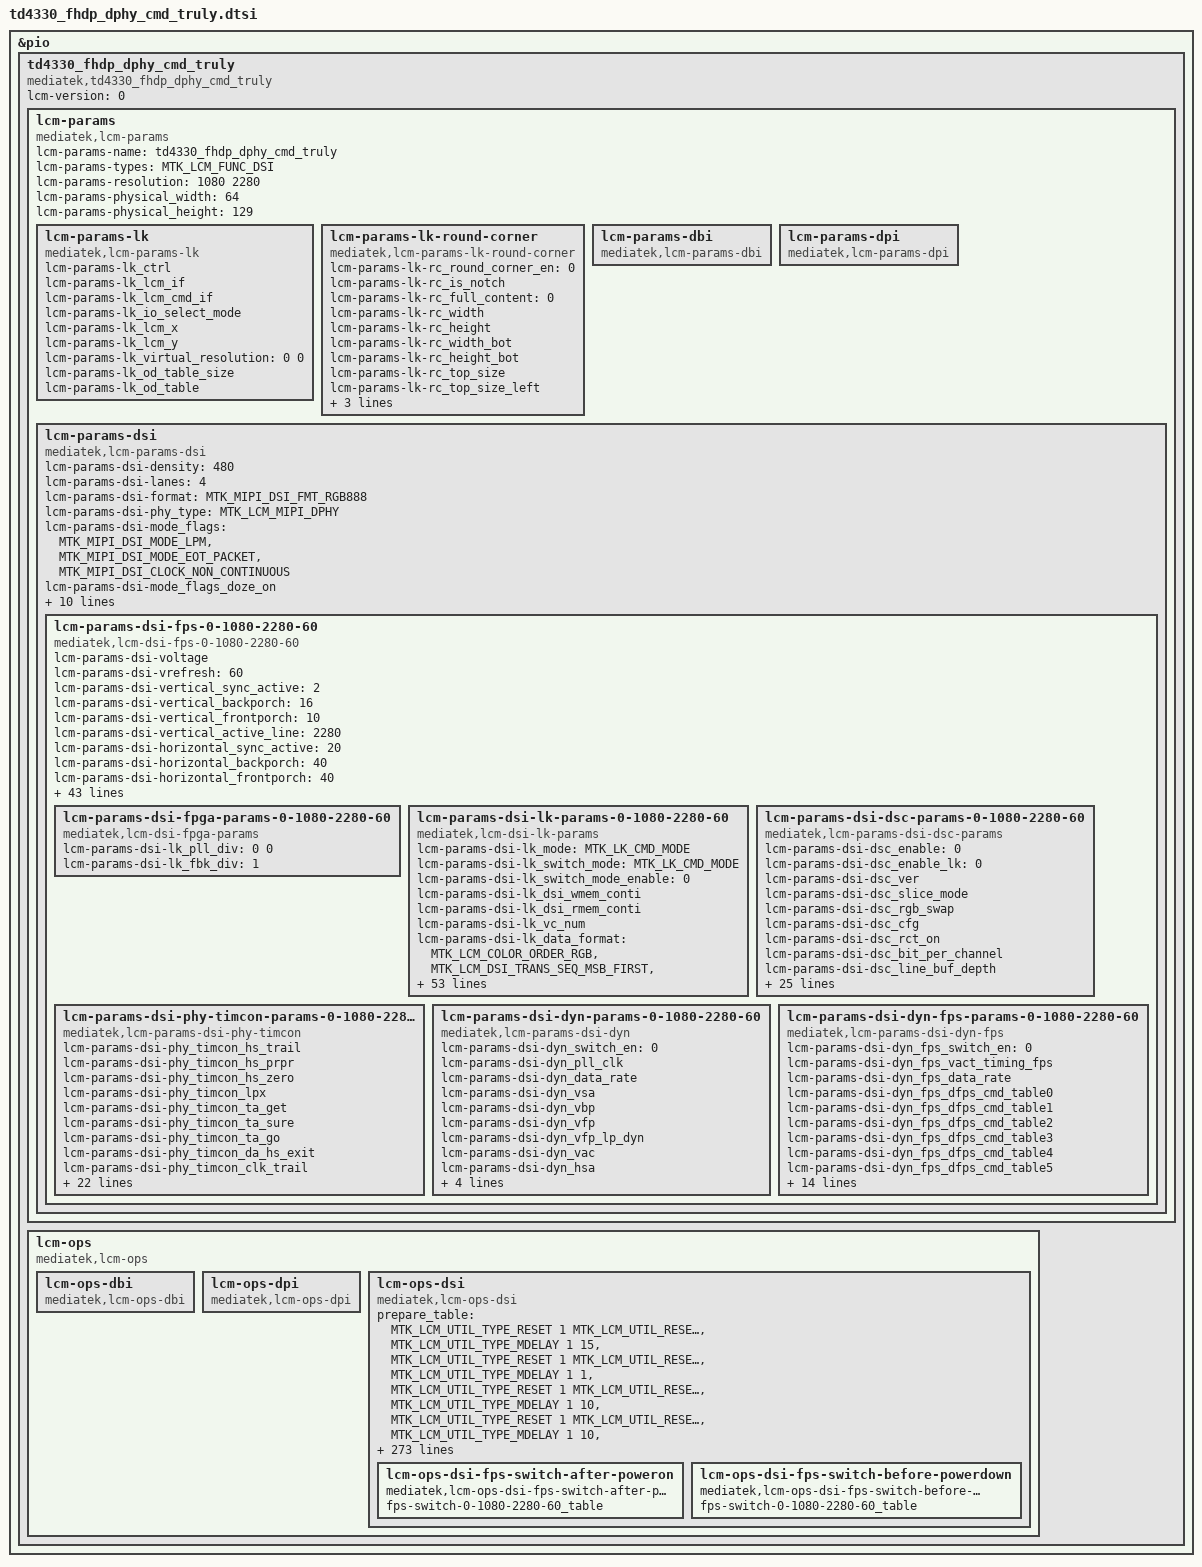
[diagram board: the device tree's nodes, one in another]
// SPDX-License-Identifier: GPL-2.0
/*
 * Device Tree defines for LCM settings
 * Copyright (c) 2021 MediaTek Inc.
 */

#include "mtk_lcm_settings.h"

&pio {
	td4330_fhdp_dphy_cmd_truly: td4330_fhdp_dphy_cmd_truly {
		compatible = "mediatek,td4330_fhdp_dphy_cmd_truly";
		lcm-version = <0>;

		lcm-params{
			compatible = "mediatek,lcm-params";
			lcm-params-name = "td4330_fhdp_dphy_cmd_truly";
			lcm-params-types = <MTK_LCM_FUNC_DSI>;
			lcm-params-resolution = <1080 2280>;
			lcm-params-physical_width = <64>;
			lcm-params-physical_height = <129>;

			/* lk support */
			lcm-params-lk {
				compatible = "mediatek,lcm-params-lk";
				lcm-params-lk_ctrl;
				lcm-params-lk_lcm_if;
				lcm-params-lk_lcm_cmd_if;
				lcm-params-lk_io_select_mode;
				lcm-params-lk_lcm_x;
				lcm-params-lk_lcm_y;
				lcm-params-lk_virtual_resolution = <0 0>;
				lcm-params-lk_od_table_size;
				lcm-params-lk_od_table;
			};

			lcm-params-lk-round-corner {
				compatible = "mediatek,lcm-params-lk-round-corner";
				lcm-params-lk-rc_round_corner_en = <0>;
				lcm-params-lk-rc_is_notch;
				lcm-params-lk-rc_full_content = <0>;
				lcm-params-lk-rc_width;
				lcm-params-lk-rc_height;
				lcm-params-lk-rc_width_bot;
				lcm-params-lk-rc_height_bot;
				lcm-params-lk-rc_top_size;
				lcm-params-lk-rc_top_size_left;
				lcm-params-lk-rc_top_size_right;
				lcm-params-lk-rc_bottom_size;
				lcm-params-lk-rc_pattern_name;
			};

			lcm-params-dbi {
				compatible = "mediatek,lcm-params-dbi";
				/* future reserved for dbi interfaces */
			};

			lcm-params-dpi {
				compatible = "mediatek,lcm-params-dpi";
				/* future reserved for dpi interfaces */
			};

			lcm-params-dsi {
				compatible = "mediatek,lcm-params-dsi";
				lcm-params-dsi-density = <480>;
				lcm-params-dsi-lanes = <4>;
				lcm-params-dsi-format = <MTK_MIPI_DSI_FMT_RGB888>;
				lcm-params-dsi-phy_type = <MTK_LCM_MIPI_DPHY>;
				lcm-params-dsi-mode_flags = <MTK_MIPI_DSI_MODE_LPM>,
						<MTK_MIPI_DSI_MODE_EOT_PACKET>,
						<MTK_MIPI_DSI_CLOCK_NON_CONTINUOUS>;
				lcm-params-dsi-mode_flags_doze_on;
				lcm-params-dsi-mode_flags_doze_off;

				lcm-params-dsi-need_fake_resolution;
				lcm-params-dsi-fake_resolution = <1080 2280>;

				lcm_gpio_list = <&pio 42 0>, /* gpio list*/
					<&pio 28 0>,
					<&pio 29 0>;
				pinctrl-names = "gpio1", "gpio2", "gpio3";
				pinctrl-0;
				pinctrl-1;
				pinctrl-2;
				status = "okay";

				lcm-params-dsi-default_mode = <0>;
				lcm-params-dsi-mode_count = <1>;
				lcm-params-dsi-mode_list =
					<0 1080 2280 60>;

				lcm-params-dsi-fps-0-1080-2280-60 {
					compatible = "mediatek,lcm-dsi-fps-0-1080-2280-60";
					lcm-params-dsi-voltage;

					/* drm_display_mode */
					lcm-params-dsi-vrefresh = <60>;
					lcm-params-dsi-vertical_sync_active = <2>;
					lcm-params-dsi-vertical_backporch = <16>;
					lcm-params-dsi-vertical_frontporch = <10>;
					lcm-params-dsi-vertical_active_line = <2280>;
					lcm-params-dsi-horizontal_sync_active = <20>;
					lcm-params-dsi-horizontal_backporch = <40>;
					lcm-params-dsi-horizontal_frontporch = <40>;
					lcm-params-dsi-horizontal_active_pixel = <1080>;
					lcm-params-dsi-pixel_clock = <163406>;
					lcm-params-dsi-hskew;
					lcm-params-dsi-vscan;

					/* mtk_panel_params */
					lcm-params-dsi-pll_clock = <525>;
					lcm-params-dsi-data_rate;
					lcm-params-dsi-vfp_for_low_power = <750>;
					lcm-params-dsi-ssc_disable;
					lcm-params-dsi-ssc_range;
					lcm-params-dsi-lcm_color_mode;
					lcm-params-dsi-min_luminance;
					lcm-params-dsi-average_luminance;
					lcm-params-dsi-max_luminance;
					lcm-params-dsi-round_corner_en = <0>;
					lcm-params-dsi-corner_pattern_height;
					lcm-params-dsi-corner_pattern_height_bot;
					lcm-params-dsi-corner_pattern_tp_size;
					lcm-params-dsi-corner_pattern_tp_size_left;
					lcm-params-dsi-corner_pattern_tp_size_right;
					lcm-params-dsi-corner_pattern_name;
					lcm-params-dsi-physical_width_um;
					lcm-params-dsi-physical_height_um;
					lcm-params-dsi-output_mode = <MTK_LCM_PANEL_SINGLE_PORT>;
					lcm-params-dsi-lcm_cmd_if;
					lcm-params-dsi-hbm_en_time;
					lcm-params-dsi-hbm_dis_time;
					lcm-params-dsi-lcm_index;
					lcm-params-dsi-wait_sof_before_dec_vfp;
					lcm-params-dsi-doze_delay;
					lcm-params-dsi-lfr_enable;
					lcm-params-dsi-lfr_minimum_fps;
					lcm-params-dsi-msync2_enable;
					lcm-params-dsi-max_vfp_for_msync;

					/* lane swap */
					lcm-params-dsi-lane_swap_en;
					lcm-params-dsi-lane_swap0;
					lcm-params-dsi-lane_swap1;

					/* esd check table */
					lcm-params-dsi-cust_esd_check = <0>;
					lcm-params-dsi-esd_check_enable = <1>;
					lcm-params-dsi-lcm_esd_check_table0 = <0x0A 0x01 0x1C 0x0>;
					lcm-params-dsi-lcm_esd_check_table1;
					lcm-params-dsi-lcm_esd_check_table2;

					/* fpga support */
					lcm-params-dsi-fpga-params-0-1080-2280-60 {
						compatible = "mediatek,lcm-dsi-fpga-params";

						lcm-params-dsi-lk_pll_div = <0 0>;
						lcm-params-dsi-lk_fbk_div = <1>;
					};

					/* lk support */
					lcm-params-dsi-lk-params-0-1080-2280-60 {
						compatible = "mediatek,lcm-dsi-lk-params";
						lcm-params-dsi-lk_mode = <MTK_LK_CMD_MODE>;
						lcm-params-dsi-lk_switch_mode = <MTK_LK_CMD_MODE>;
						lcm-params-dsi-lk_switch_mode_enable = <0>;
						lcm-params-dsi-lk_dsi_wmem_conti;
						lcm-params-dsi-lk_dsi_rmem_conti;
						lcm-params-dsi-lk_vc_num;
						lcm-params-dsi-lk_data_format =
							<MTK_LCM_COLOR_ORDER_RGB>,
							<MTK_LCM_DSI_TRANS_SEQ_MSB_FIRST>,
							<MTK_LCM_DSI_PADDING_ON_LSB>,
							<MTK_LCM_DSI_FORMAT_RGB888>;
						lcm-params-dsi-lk_intermediat_buffer_num;
						lcm-params-dsi-lk_ps =
							<MTK_LCM_PACKED_PS_24BIT_RGB888>;
						lcm-params-dsi-lk_word_count;
						lcm-params-dsi-lk_packet_size = <256>;

						lcm-params-dsi-lk_horizontal_blanking_pixel;
						lcm-params-dsi-lk_bllp;
						lcm-params-dsi-lk_line_byte;
						lcm-params-dsi-lk_horizontal_sync_active_byte;
						lcm-params-dsi-lk_horizontal_backporch_byte;
						lcm-params-dsi-lk_horizontal_frontporch_byte;
						lcm-params-dsi-lk_rgb_byte;
						lcm-params-dsi-lk_horizontal_sync_active_word_count;
						lcm-params-dsi-lk_horizontal_backporch_word_count;
						lcm-params-dsi-lk_horizontal_frontporch_word_count;
						lcm-params-dsi-lk_pll_select;
						lcm-params-dsi-lk_pll_div;
						lcm-params-dsi-lk_fbk_div;
						lcm-params-dsi-lk_fbk_sel;
						lcm-params-dsi-lk_rg = <0 0 0>;
						lcm-params-dsi-lk_dsi_clock;
						lcm-params-dsi-lk_ssc_disable = <1>;
						lcm-params-dsi-lk_ssc_range;
						lcm-params-dsi-lk_compatibility_for_nvk;
						lcm-params-dsi-lk_cont_clock;
						lcm-params-dsi-lk_ufoe_enable;
						lcm-params-dsi-lk_ufoe_params = <0 0 0 0>;
						lcm-params-dsi-lk_edp_panel;
						lcm-params-dsi-lk_lcm_int_te_monitor;
						lcm-params-dsi-lk_lcm_int_te_period;
						lcm-params-dsi-lk_lcm_ext_te_monitor;
						lcm-params-dsi-lk_lcm_ext_te_period;
						lcm-params-dsi-lk_noncont_clock;
						lcm-params-dsi-lk_noncont_clock_period;
						lcm-params-dsi-lk_clk_lp_per_line_enable;
						lcm-params-dsi-lk_dual_dsi_type;
						lcm-params-dsi-lk_mixmode_enable;
						lcm-params-dsi-lk_mixmode_mipi_clock;
						lcm-params-dsi-lk_pwm_fps;
						lcm-params-dsi-lk_pll_clock_lp;
						lcm-params-dsi-lk_ulps_sw_enable;
						lcm-params-dsi-lk_null_packet_en;
						lcm-params-dsi-lk_vact_fps;
						lcm-params-dsi-lk_send_frame_enable;
						lcm-params-dsi-lk_lfr_enable;
						lcm-params-dsi-lk_lfr_mode;
						lcm-params-dsi-lk_lfr_type;
						lcm-params-dsi-lk_lfr_skip_num;
						lcm-params-dsi-lk_ext_te_edge;
						lcm-params-dsi-lk_eint_disable;
						lcm-params-dsi-lk_phy_sel = <0 0 0 0>;
					};

					lcm-params-dsi-dsc-params-0-1080-2280-60 {
						compatible =
							"mediatek,lcm-params-dsi-dsc-params";
						lcm-params-dsi-dsc_enable = <0>;
						lcm-params-dsi-dsc_enable_lk = <0>;
						lcm-params-dsi-dsc_ver;
						lcm-params-dsi-dsc_slice_mode;
						lcm-params-dsi-dsc_rgb_swap;
						lcm-params-dsi-dsc_cfg;
						lcm-params-dsi-dsc_rct_on;
						lcm-params-dsi-dsc_bit_per_channel;
						lcm-params-dsi-dsc_line_buf_depth;
						lcm-params-dsi-dsc_bp_enable;
						lcm-params-dsi-dsc_bit_per_pixel;
						lcm-params-dsi-dsc_pic_height;
						lcm-params-dsi-dsc_pic_width;
						lcm-params-dsi-dsc_slice_height;
						lcm-params-dsi-dsc_slice_width;
						lcm-params-dsi-dsc_chunk_size;
						lcm-params-dsi-dsc_xmit_delay;
						lcm-params-dsi-dsc_dec_delay;
						lcm-params-dsi-dsc_scale_value;
						lcm-params-dsi-dsc_increment_interval;
						lcm-params-dsi-dsc_decrement_interval;
						lcm-params-dsi-dsc_line_bpg_offset;
						lcm-params-dsi-dsc_nfl_bpg_offset;
						lcm-params-dsi-dsc_slice_bpg_offset;
						lcm-params-dsi-dsc_initial_offset;
						lcm-params-dsi-dsc_final_offset;
						lcm-params-dsi-dsc_flatness_minqp;
						lcm-params-dsi-dsc_flatness_maxqp;
						lcm-params-dsi-dsc_rc_model_size;
						lcm-params-dsi-dsc_rc_edge_factor;
						lcm-params-dsi-dsc_rc_quant_incr_limit0;
						lcm-params-dsi-dsc_rc_quant_incr_limit1;
						lcm-params-dsi-dsc_rc_tgt_offset_hi;
						lcm-params-dsi-dsc_rc_tgt_offset_lo;
					};

					lcm-params-dsi-phy-timcon-params-0-1080-2280-60 {
						compatible =
							"mediatek,lcm-params-dsi-phy-timcon";
						lcm-params-dsi-phy_timcon_hs_trail;
						lcm-params-dsi-phy_timcon_hs_prpr;
						lcm-params-dsi-phy_timcon_hs_zero;
						lcm-params-dsi-phy_timcon_lpx;
						lcm-params-dsi-phy_timcon_ta_get;
						lcm-params-dsi-phy_timcon_ta_sure;
						lcm-params-dsi-phy_timcon_ta_go;
						lcm-params-dsi-phy_timcon_da_hs_exit;
						lcm-params-dsi-phy_timcon_clk_trail;
						lcm-params-dsi-phy_timcon_cont_det;
						lcm-params-dsi-phy_timcon_da_hs_sync;
						lcm-params-dsi-phy_timcon_clk_zero;
						lcm-params-dsi-phy_timcon_clk_prpr;
						lcm-params-dsi-phy_timcon_clk_exit;
						lcm-params-dsi-phy_timcon_clk_post;

						/* lk support */
						lcm-params-dsi-phy_timcon_lk_hs_trail;
						lcm-params-dsi-phy_timcon_lk_hs_zero;
						lcm-params-dsi-phy_timcon_lk_hs_prpr;
						lcm-params-dsi-phy_timcon_lk_lpx;
						lcm-params-dsi-phy_timcon_lk_ta_sack;
						lcm-params-dsi-phy_timcon_lk_ta_get;
						lcm-params-dsi-phy_timcon_lk_ta_sure;
						lcm-params-dsi-phy_timcon_lk_ta_go;
						lcm-params-dsi-phy_timcon_lk_clk_trail;
						lcm-params-dsi-phy_timcon_lk_clk_zero;
						lcm-params-dsi-phy_timcon_lk_lpx_wait;
						lcm-params-dsi-phy_timcon_lk_cont_det;
						lcm-params-dsi-phy_timcon_lk_clk_hs_prpr;
						lcm-params-dsi-phy_timcon_lk_clk_hs_post;
						lcm-params-dsi-phy_timcon_lk_da_hs_exit;
						lcm-params-dsi-phy_timcon_lk_clk_hs_exit;
					};

					lcm-params-dsi-dyn-params-0-1080-2280-60 {
						compatible =
							"mediatek,lcm-params-dsi-dyn";
						lcm-params-dsi-dyn_switch_en = <0>;
						lcm-params-dsi-dyn_pll_clk;
						lcm-params-dsi-dyn_data_rate;
						lcm-params-dsi-dyn_vsa;
						lcm-params-dsi-dyn_vbp;
						lcm-params-dsi-dyn_vfp;
						lcm-params-dsi-dyn_vfp_lp_dyn;
						lcm-params-dsi-dyn_vac;
						lcm-params-dsi-dyn_hsa;
						lcm-params-dsi-dyn_hbp;
						lcm-params-dsi-dyn_hfp;
						lcm-params-dsi-dyn_hac;
						lcm-params-dsi-dyn_max_vfp_for_msync_dyn;
					};

					lcm-params-dsi-dyn-fps-params-0-1080-2280-60 {
						compatible =
							"mediatek,lcm-params-dsi-dyn-fps";
						lcm-params-dsi-dyn_fps_switch_en = <0>;
						lcm-params-dsi-dyn_fps_vact_timing_fps;
						lcm-params-dsi-dyn_fps_data_rate;
						lcm-params-dsi-dyn_fps_dfps_cmd_table0;
						lcm-params-dsi-dyn_fps_dfps_cmd_table1;
						lcm-params-dsi-dyn_fps_dfps_cmd_table2;
						lcm-params-dsi-dyn_fps_dfps_cmd_table3;
						lcm-params-dsi-dyn_fps_dfps_cmd_table4;
						lcm-params-dsi-dyn_fps_dfps_cmd_table5;
						lcm-params-dsi-dyn_fps_dfps_cmd_table6;
						lcm-params-dsi-dyn_fps_dfps_cmd_table7;
						lcm-params-dsi-dyn_fps_dfps_cmd_table8;
						lcm-params-dsi-dyn_fps_dfps_cmd_table9;
						lcm-params-dsi-dyn_fps_dfps_cmd_table10;
						lcm-params-dsi-dyn_fps_dfps_cmd_table11;
						lcm-params-dsi-dyn_fps_dfps_cmd_table12;
						lcm-params-dsi-dyn_fps_dfps_cmd_table13;
						lcm-params-dsi-dyn_fps_dfps_cmd_table14;
						lcm-params-dsi-dyn_fps_dfps_cmd_table15;
						lcm-params-dsi-dyn_fps_dfps_cmd_table16;
						lcm-params-dsi-dyn_fps_dfps_cmd_table17;
						lcm-params-dsi-dyn_fps_dfps_cmd_table18;
						lcm-params-dsi-dyn_fps_dfps_cmd_table19;
					};
				};
			};
		};

		lcm-ops {
			compatible = "mediatek,lcm-ops";
			lcm-ops-dbi {
				compatible = "mediatek,lcm-ops-dbi";
				/* future reserved for dbi interfaces*/
			};

			lcm-ops-dpi {
				compatible = "mediatek,lcm-ops-dpi";
				/* future reserved for dpi interfaces*/
			};

			lcm-ops-dsi {
				compatible = "mediatek,lcm-ops-dsi";
				prepare_table = <MTK_LCM_UTIL_TYPE_RESET 1 MTK_LCM_UTIL_RESET_LOW>,
					<MTK_LCM_UTIL_TYPE_MDELAY 1 15>,
					<MTK_LCM_UTIL_TYPE_RESET 1 MTK_LCM_UTIL_RESET_HIGH>,
					<MTK_LCM_UTIL_TYPE_MDELAY 1 1>,
					<MTK_LCM_UTIL_TYPE_RESET 1 MTK_LCM_UTIL_RESET_LOW>,
					<MTK_LCM_UTIL_TYPE_MDELAY 1 10>,
					<MTK_LCM_UTIL_TYPE_RESET 1 MTK_LCM_UTIL_RESET_HIGH>,
					<MTK_LCM_UTIL_TYPE_MDELAY 1 10>,
					<MTK_LCM_CMD_TYPE_WRITE_BUFFER 2 0xB0 0x00>,
					<MTK_LCM_CMD_TYPE_WRITE_BUFFER 13>,
						<0xB6 0x30 0x6B 0x00 0x06 0x03 0x0A 0x13 0x1A 0x6C>,
						<0x18 0x19 0x02>,
					<MTK_LCM_CMD_TYPE_WRITE_BUFFER 5>,
						<0xB7 0x40 0x00 0x00 0x00>,
					<MTK_LCM_CMD_TYPE_WRITE_BUFFER 8>,
						<0xB8 0x57 0x3d 0x19 0xbe 0x1e 0x0a 0x0a>,
					<MTK_LCM_CMD_TYPE_WRITE_BUFFER 8>,
						<0xB9 0x6f 0x3d 0x28 0xbe 0x3c 0x14 0x0a>,
					<MTK_LCM_CMD_TYPE_WRITE_BUFFER 8>,
						<0xBA 0xb5 0x33 0x41 0xbe 0x64 0x23 0x0a>,
					<MTK_LCM_CMD_TYPE_WRITE_BUFFER 12>,
						<0xBB 0x44 0x26 0xC3 0x1F 0x19 0x06 0x03 0xC0 0x00>,
						<0x00 0x10>,
					<MTK_LCM_CMD_TYPE_WRITE_BUFFER 12>,
						<0xBC 0x32 0x4C 0xC3 0x52 0x32 0x1F 0x03 0xF2 0x00>,
						<0x00 0x13>,
					<MTK_LCM_CMD_TYPE_WRITE_BUFFER 12>,
						<0xBD 0x24 0x68 0xC3 0xAA 0x3F 0x32 0x03 0xFF 0x00>,
						<0x00 0x25>,
					<MTK_LCM_CMD_TYPE_WRITE_BUFFER 13>,
						<0xBE 0x00 0x00 0x00 0x00 0x00 0x00 0x00 0x00 0x00>,
						<0x00 0x00 0x00>,
					<MTK_LCM_CMD_TYPE_WRITE_BUFFER 13>,
						<0xC0 0x00 0xDB 0x00 0xDB 0x04 0x08 0xE8 0x00 0x04>,
						<0x00 0x03 0x78>,
					<MTK_LCM_CMD_TYPE_WRITE_BUFFER 36>,
						<0xC1 0x30 0x00 0x00 0x11 0x11 0x00 0x00 0x00 0x22>,
						<0x00 0x05 0x20 0xFA 0x00 0x08 0x00 0x00 0x00 0x00>,
						<0x00 0x00 0x00 0x00 0x00 0x00 0x00 0x00 0x00 0x00>,
						<0x00 0x00 0x00 0x00 0x00 0x00>,
					<MTK_LCM_CMD_TYPE_WRITE_BUFFER 121>,
						<0xC2 0x06 0xE0 0x6E 0x01 0x03 0x00 0x02 0x00 0x00>,
						<0x00 0x00 0x00 0x00 0x00 0x00 0x00 0x00 0x00 0x00>,
						<0x00 0x00 0x00 0x00 0x00 0x00 0x00 0x00 0x00 0x00>,
						<0x00 0x00 0x00 0x00 0x00 0x00 0x00 0x00 0x00 0x00>,
						<0x00 0x00 0x11 0x00 0x00 0x00 0x00 0x04 0xA0 0xC9>,
						<0x00 0x00 0x00 0x00 0x00 0x00 0x48 0xEB 0x00 0x00>,
						<0x01 0x00 0x00 0x00 0x11 0x00 0x00 0x00 0x00 0x00>,
						<0x00 0x00 0x00 0x00 0x00 0x00 0x00 0x00 0x00 0x00>,
						<0x00 0x00 0x00 0x00 0x00 0x11 0x00 0x00 0x00 0x00>,
						<0x00 0x00 0xDC 0x00 0x00 0x00 0x00 0x04 0x00 0x08>,
						<0xEF 0x00 0x00 0x00 0x00 0x00 0x11 0x00 0x00 0x00>,
						<0x00 0x00 0x00 0x00 0x00 0x00 0x00 0x00 0x00 0x00>,
						<0x00>,
					<MTK_LCM_CMD_TYPE_WRITE_BUFFER 109>,
						<0xC3 0x00 0x00 0x00 0x00 0x00 0x00 0x00 0x00 0x00>,
						<0x00 0x00 0x00 0x00 0x00 0x00 0x00 0x00 0x00 0x00>,
						<0x00 0x00 0x00 0x00 0x00 0x00 0x00 0x00 0x00 0x00>,
						<0x00 0x00 0x00 0x00 0x00 0x00 0x00 0x00 0x00 0x00>,
						<0x00 0x00 0x00 0x00 0x00 0x00 0x00 0x00 0x00 0x00>,
						<0x00 0x00 0x00 0x00 0x00 0x00 0x00 0x00 0x00 0x00>,
						<0x00 0x00 0x00 0xaa 0xaa 0xaa 0x00 0x00 0x00 0x00>,
						<0x00 0x00 0x00 0x00 0x00 0x00 0x00 0x00 0x00 0x00>,
						<0x00 0x00 0x00 0x00 0x00 0x00 0x00 0x00 0x00 0x00>,
						<0x00 0x00 0x00 0x00 0x00 0x00 0x00 0x00 0x00 0x00>,
						<0x00 0x00 0x00 0x00 0x00 0x00 0x00 0x00 0x00>,
					<MTK_LCM_CMD_TYPE_WRITE_BUFFER 98>,
						<0xC4 0x00 0x4c 0x00 0x3f 0x00 0x83 0x00 0x00 0x87>,
						<0x86 0x85 0x84 0x00 0x00 0x00 0x00 0x00 0x61 0x5d>,
						<0x5f 0x00 0x5e 0x60 0x62 0x00 0x00 0x00 0x02 0x00>,
						<0x83 0x00 0x00 0x87 0x86 0x85 0x84 0x00 0x00 0x00>,
						<0x00 0x00 0x61 0x5d 0x5f 0x00 0x5e 0x60 0x62 0xff>,
						<0xff 0xff 0xff 0xff 0xff 0x00 0x0f 0x0e 0x00 0x0f>,
						<0x0e 0x00 0x00 0x00 0x00 0x00 0x00 0x00 0x0f 0xee>,
						<0x00 0x0f 0xee 0x00 0x00 0xe0 0x00 0x00 0xe0 0x0e>,
						<0x00 0x00 0x00 0x0e 0x00 0x00 0x00 0x00 0x00 0xff>,
						<0x57 0x00 0x00 0x00 0x00 0x00 0x00 0x00>,
					<MTK_LCM_CMD_TYPE_WRITE_BUFFER 6>,
						<0xC5 0x08 0x00 0x00 0x00 0x00>,
					<MTK_LCM_CMD_TYPE_WRITE_BUFFER 58>,
						<0xC6 0x02 0x0a 0x08 0xfc 0xff 0xff 0xff 0x00 0x00>,
						<0x13 0x01 0xf0 0x0c 0x06 0x01 0x43 0x43 0x43 0x00>,
						<0x00 0x00 0x01 0x77 0x09 0x28 0x28 0x06 0x01 0x43>,
						<0x43 0x43 0x00 0x00 0x00 0x01 0x61 0x00 0x00 0x00>,
						<0x1c 0x01 0x00 0x00 0x00 0x00 0x00 0x00 0x00 0x00>,
						<0x00 0x00 0x00 0x00 0x20 0x20 0x00 0x00>,
					<MTK_LCM_CMD_TYPE_WRITE_BUFFER 77>,
						<0xC7 0x00 0x00 0x00 0xe0 0x01 0xE9 0x02 0x7e 0x02>,
						<0x05 0x02 0x90 0x02 0xf6 0x02 0x40 0x02 0x5C 0x02>,
						<0x77 0x02 0xC8 0x02 0x1b 0x02 0x5b 0x02 0xBd 0x02>,
						<0x27 0x02 0xc3 0x03 0x54 0x03 0xd8 0x03 0xff 0x00>,
						<0x00 0x00 0xe0 0x01 0xE9 0x02 0x7e 0x02 0x05 0x02>,
						<0x90 0x02 0xf6 0x02 0x40 0x02 0x5C 0x02 0x77 0x02>,
						<0xC8 0x02 0x1b 0x02 0x5b 0x02 0xBd 0x02 0x27 0x02>,
						<0xc3 0x03 0x54 0x03 0xd8 0x03 0xff>,
					<MTK_LCM_CMD_TYPE_WRITE_BUFFER 66>,
						<0xC8 0x41 0x00 0xff 0xfa 0x00 0xff 0x00 0x00 0xfe>,
						<0xf6 0xfe 0xe9 0x00 0x00 0xff 0xf7 0xfb 0xe1 0x00>,
						<0x00 0x00 0x00 0x00 0xff 0x00 0x00 0xff 0xfa 0x00>,
						<0xff 0x00 0xfe 0xf6 0xfe 0xe9 0x00 0xff 0xf7 0xfb>,
						<0xe1 0x00 0x00 0x00 0x00 0xff 0x00 0xff 0xfa 0x00>,
						<0xff 0x00 0xfe 0xf6 0xfe 0xe9 0x00 0xff 0xf7 0xfb>,
						<0xe1 0x00 0x00 0x00 0x00 0xff>,
					<MTK_LCM_CMD_TYPE_WRITE_BUFFER 25>,
						<0xC9 0x00 0xff 0xfa 0x00 0xff 0x00 0x00 0xfe 0xf6>,
						<0xfe 0xe9 0x00 0x00 0xff 0xf7 0xfb 0xe1 0x00 0x00>,
						<0x00 0x00 0x00 0xff 0x00>,
					<MTK_LCM_CMD_TYPE_WRITE_BUFFER 66>,
						<0xCA 0x1c 0xfc 0xfc 0xfc 0x00 0x00 0x00 0x00 0x00>,
						<0x00 0x00 0x00 0x00 0x00 0x00 0x00 0x00 0x00 0x00>,
						<0x00 0x00 0x00 0x00 0x00 0x00 0x00 0x00 0x00 0x00>,
						<0x00 0x00 0x00 0x00 0x00 0x00 0x00 0x00 0x00 0x00>,
						<0x00 0x00 0x00 0x00 0x00 0x00 0x00 0x00 0x00 0x00>,
						<0x00 0x00 0x00 0x00 0x00 0x00 0x00 0x00 0x00 0x00>,
						<0x00 0x00 0x00 0x00 0x00 0x00>,
					<MTK_LCM_CMD_TYPE_WRITE_BUFFER 11>,
						<0xCC 0x00 0x00 0x4d 0x8b 0x55 0x4d 0x8b 0xaa 0x4d>,
						<0x8b>,
					<MTK_LCM_CMD_TYPE_WRITE_BUFFER 2 0xCD 0x00>,
					<MTK_LCM_CMD_TYPE_WRITE_BUFFER 36>,
						<0xCE 0x5d 0x40 0x49 0x53 0x59 0x5e 0x63 0x68 0x6e>,
						<0x74 0x7e 0x8a 0x98 0xa8 0xbb 0xd0 0xe7 0xff 0x04>,
						<0x00 0x04 0x04 0x42 0x04 0x69 0x5a 0x40 0x11 0xf4>,
						<0x00 0x00 0x84 0xfa 0x00 0x00>,
					<MTK_LCM_CMD_TYPE_WRITE_BUFFER 7>,
						<0xCF 0x00 0x00 0x80 0x46 0x61 0x00>,
					<MTK_LCM_CMD_TYPE_WRITE_BUFFER 18>,
						<0xD0 0xf6 0x95 0x11 0xb1 0x55 0xcf 0x00 0xf6 0xd3>,
						<0x11 0xf0 0x01 0x12 0xcf 0x02 0x20 0x11>,
					<MTK_LCM_CMD_TYPE_WRITE_BUFFER 35>,
						<0xD1 0xd3 0xd3 0x33 0x33 0x07 0x03 0x3b 0x33 0x77>,
						<0x37 0x77 0x37 0x35 0x77 0x07 0x77 0xf7 0x33 0x73>,
						<0x07 0x33 0x33 0x03 0x33 0x1b 0x03 0x32 0x3d 0x0a>,
						<0x30 0x13 0x13 0x20 0x00>,
					<MTK_LCM_CMD_TYPE_WRITE_BUFFER 4 0xD2 0x00 0x00 0x07>,
					<MTK_LCM_CMD_TYPE_WRITE_BUFFER 154>,
						<0xD3 0x03 0x00 0x00 0x00 0x00 0x00 0x00 0x0f 0x00>,
						<0x57 0x00 0x00 0x32 0x00 0x00 0x1a 0x70 0x01 0x19>,
						<0x80 0x01 0x01 0xf0 0x02 0x00 0xe0 0x06 0xff 0xf7>,
						<0xff 0xff 0xf7 0xff 0xff 0xf7 0xff 0xff 0xf7 0xff>,
						<0xff 0xf7 0xff 0xff 0xf7 0xff 0xff 0xf7 0xff 0xff>,
						<0xf7 0xff 0xff 0xf7 0xff 0xff 0xf7 0xff 0xff 0xf7>,
						<0xff 0xff 0xf7 0xff 0xff 0xf7 0xff 0xff 0xf7 0xff>,
						<0xff 0xf7 0xff 0xff 0xf7 0xff 0xff 0xf7 0xff 0xff>,
						<0xf7 0xff 0xff 0xf7 0xff 0xff 0xf7 0xff 0xff 0xf7>,
						<0xff 0xff 0xf7 0xff 0xff 0xf7 0xff 0xff 0xf7 0xff>,
						<0xff 0xf7 0xff 0xff 0xf7 0xff 0xff 0xf7 0xff 0xff>,
						<0xf7 0xff 0xff 0xf7 0xff 0xff 0xf7 0xff 0xff 0xf7>,
						<0xff 0xff 0xf7 0xff 0xff 0xf7 0xff 0xff 0xf7 0xff>,
						<0xff 0xf7 0xff 0xff 0xf7 0xff 0xff 0xf7 0xff 0xff>,
						<0xf7 0xff 0xff 0xf7 0xff 0xff 0xf7 0xff 0xff 0xf7>,
						<0xff 0xff 0xf7 0xff>,
					<MTK_LCM_CMD_TYPE_WRITE_BUFFER 5>,
						<0xE5 0x03 0x00 0x00 0x00>,
					<MTK_LCM_CMD_TYPE_WRITE_BUFFER 9>,
						<0xD5 0x02 0x42 0x02 0x42 0x02 0xdc 0x02 0xdc>,
					<MTK_LCM_CMD_TYPE_WRITE_BUFFER 2 0xD6 0xc0>,
					<MTK_LCM_CMD_TYPE_WRITE_BUFFER 50>,
						<0xD7 0x21 0x10 0x52 0x52 0x00 0xB6 0x04 0xFD 0x00>,
						<0xB6 0x04 0xFD 0x00 0x82 0x80 0x83 0x84 0x85 0x83>,
						<0x80 0x84 0x45 0x85 0x85 0x85 0x87 0x04 0x06 0x02>,
						<0x04 0x04 0x07 0x10 0x0C 0x0B 0x0A 0x0A 0x07 0x06>,
						<0x00 0x08 0x00 0x00 0x00 0x00 0x00 0x00 0x00 0x00>,
					<MTK_LCM_CMD_TYPE_WRITE_BUFFER 5 0xDD 0x30 0x06 0x23 0x65>,
					<MTK_LCM_CMD_TYPE_WRITE_BUFFER 13>,
						<0xDE 0x00 0x00 0x00 0x0f 0xff 0x00 0x00 0x00 0x00>,
						<0x00 0x00 0x10>,
					<MTK_LCM_CMD_TYPE_WRITE_BUFFER 2 0xE3 0xff>,
					<MTK_LCM_CMD_TYPE_WRITE_BUFFER 7>,
						<0xE6 0x00 0x00 0x00 0x00 0x00 0x00>,
					<MTK_LCM_CMD_TYPE_WRITE_BUFFER 11>,
						<0xE7 0x50 0x04 0x00 0x00 0x00 0x00 0x00 0x00 0x00>,
						<0x00>,
					<MTK_LCM_CMD_TYPE_WRITE_BUFFER 5 0xE8 0x00 0x01 0x23 0x00>,
					<MTK_LCM_CMD_TYPE_WRITE_BUFFER 30>,
						<0xEA 0x01 0x02 0x47 0x80 0x47 0x00 0x00 0x00 0x05>,
						<0x00 0x13 0x60 0x02 0x47 0x80 0x47 0x00 0x00 0x00>,
						<0x00 0x13 0x60 0x00 0x11 0x00 0x30 0x10 0x21 0x02>,
					<MTK_LCM_CMD_TYPE_WRITE_BUFFER 8>,
						<0xEB 0x00 0x00 0x00 0x00 0x01 0x00 0x11>,
					<MTK_LCM_CMD_TYPE_WRITE_BUFFER 4 0xEC 0x00 0x00 0x00>,
					<MTK_LCM_CMD_TYPE_WRITE_BUFFER 33>,
						<0xED 0x01 0x01 0x02 0x02 0x02 0x02 0x00 0x00 0x00>,
						<0x00 0x00 0x00 0x0A 0x00 0x00 0x00 0x00 0x10 0x00>,
						<0x18 0x00 0x18 0x00 0xB0 0x00 0x00 0x00 0x00 0x00>,
						<0xDA 0x10 0x00>,
					<MTK_LCM_CMD_TYPE_WRITE_BUFFER 97>,
						<0xEE 0x03 0x0F 0x00 0x00 0x00 0x00 0x40 0x1F 0x00>,
						<0x00 0x0F 0xF2 0x3F 0x00 0x00 0x00 0x00 0x00 0x00>,
						<0x00 0x00 0x00 0x00 0x00 0x00 0x00 0x00 0x00 0x10>,
						<0x01 0x00 0x09 0x01 0x8C 0xD8 0xEF 0x00 0x00 0x00>,
						<0x00 0x00 0x00 0x00 0x00 0x00 0x00 0x00 0x00 0x00>,
						<0x00 0x00 0x00 0x00 0x00 0x50 0x1F 0x00 0x00 0x00>,
						<0x00 0x00 0x00 0x00 0x00 0x00 0x00 0x00 0x00 0x00>,
						<0x00 0x00 0x00 0x00 0x00 0x00 0x00 0x00 0x00 0x00>,
						<0x00 0x00 0x00 0x00 0x00 0x00 0x00 0x00 0x00 0x00>,
						<0x00 0x00 0x00 0x00 0x00 0x00 0x00>,
					<MTK_LCM_CMD_TYPE_WRITE_BUFFER 140>,
						<0xEF 0x00 0x70 0x4A 0x08 0xD0 0x00 0x00 0x00 0x00>,
						<0x3C 0x3C 0x3C 0x00 0x00 0x00 0x00 0x00 0x00 0x00>,
						<0x00 0x00 0x00 0x00 0x00 0x00 0x00 0x00 0x00 0x70>,
						<0x4A 0x08 0xD0 0x00 0x00 0x00 0x00 0x3C 0x3C 0x3C>,
						<0x00 0x00 0x00 0x00 0x00 0x00 0x00 0x00 0x00 0x00>,
						<0x00 0x00 0x00 0x00 0x00 0x00 0x00 0x00 0x00 0x00>,
						<0x00 0x00 0x00 0x00 0x00 0x00 0x00 0x00 0x00 0x00>,
						<0x00 0x00 0x00 0x00 0x00 0x00 0x00 0x00 0x00 0x00>,
						<0x00 0x00 0x00 0x00 0x00 0x00 0x00 0x00 0x00 0x00>,
						<0x00 0x00 0x00 0x03 0x08 0xEC 0x50 0x10 0x00 0x10>,
						<0x00 0x0A 0x0A 0x00 0x00 0x00 0x00 0x10 0x0F 0x00>,
						<0x03 0x51 0x00 0x50 0x00 0x00 0x00 0x00 0x00 0x00>,
						<0x00 0x00 0x00 0x00 0x00 0x00 0x00 0x00 0x00 0x00>,
						<0x00 0x00 0x00 0x00 0x00 0x00 0x00 0x03 0x08 0xEC>,
					<MTK_LCM_CMD_TYPE_WRITE_BUFFER 2 0xB0 0x03>,
					<MTK_LCM_CMD_TYPE_WRITE_BUFFER 2 0xB0 0x04>,
					<MTK_LCM_CMD_TYPE_WRITE_BUFFER 2 0xD6 0x00>,
					<MTK_LCM_CMD_TYPE_WRITE_BUFFER 3 0x51 0xff 0xf0>,
					<MTK_LCM_CMD_TYPE_WRITE_BUFFER 2 0x53 0x0c>,
					<MTK_LCM_CMD_TYPE_WRITE_BUFFER 2 0x55 0x00>,
					<MTK_LCM_CMD_TYPE_WRITE_BUFFER 2 0x35 0x00>,
					<MTK_LCM_CMD_TYPE_WRITE_BUFFER 5>,
						<0x2A 0x00 0x00 0x04 0x37>,
					<MTK_LCM_CMD_TYPE_WRITE_BUFFER 5>,
						<0x2B 0x00 0x00 0x08 0xE7>,
					<MTK_LCM_CMD_TYPE_WRITE_BUFFER 1 0x11>,
					<MTK_LCM_PHASE_TYPE_START 2>,
						<MTK_LCM_PHASE_KERNEL MTK_LCM_PHASE_LK>,
					<MTK_LCM_UTIL_TYPE_MDELAY 1 200>,
					<MTK_LCM_CMD_TYPE_WRITE_BUFFER 1 0x29>,
					<MTK_LCM_UTIL_TYPE_MDELAY 1 100>,
					<MTK_LCM_PHASE_TYPE_END 2>,
						<MTK_LCM_PHASE_KERNEL MTK_LCM_PHASE_LK>,
					<MTK_LCM_TYPE_END>;

				unprepare_table = <MTK_LCM_CMD_TYPE_WRITE_BUFFER 1 0x28>,
					<MTK_LCM_UTIL_TYPE_MDELAY 1 50>,
					<MTK_LCM_CMD_TYPE_WRITE_BUFFER 1 0x10>,
					<MTK_LCM_UTIL_TYPE_MDELAY 1 150>,
					<MTK_LCM_TYPE_END>;

				set_display_on_table =
					<MTK_LCM_PHASE_TYPE_START 2>,
						<MTK_LCM_PHASE_LK>,
						<MTK_LCM_PHASE_LK_DISPLAY_ON_DELAY>,
					<MTK_LCM_UTIL_TYPE_TDELAY 1 120>,
					<MTK_LCM_CMD_TYPE_WRITE_BUFFER 1 0x29>,
					<MTK_LCM_UTIL_TYPE_MDELAY 1 100>,
					<MTK_LCM_PHASE_TYPE_END 2>,
						<MTK_LCM_PHASE_LK>,
						<MTK_LCM_PHASE_LK_DISPLAY_ON_DELAY>,
					<MTK_LCM_TYPE_END>;

				lcm_update_table;

				set_backlight_mask = <0xff>;
				set_backlight_cmdq_table =
					<MTK_LCM_CB_TYPE_RUNTIME_INPUT 3 1 0x51 0xFF>,
					<MTK_LCM_TYPE_END>;

				set_aod_light_mask = <0xff>;
				set_aod_light_table;

				ata_id_value_length = <3>;
				ata_id_value_data = <0x0 0x0 0x0>;
				ata_check_table =
					<MTK_LCM_CMD_TYPE_READ_CMD 3 0 3 0x4>,
					<MTK_LCM_TYPE_END>;

				compare_id_value_length = <1>;
				compare_id_value_data = <0x2>;
				compare_id_table = <MTK_LCM_UTIL_TYPE_RESET 1 1>,
					<MTK_LCM_UTIL_TYPE_RESET 1 0>,
					<MTK_LCM_UTIL_TYPE_MDELAY 1 1>,
					<MTK_LCM_UTIL_TYPE_RESET 1 1>,
					<MTK_LCM_UTIL_TYPE_MDELAY 1 20>,
					<MTK_LCM_LK_TYPE_PREPARE_PARAM_COUNT 1 1>,
					<MTK_LCM_LK_TYPE_PREPARE_PARAM 5 0 0x0 0x1 0x37 0x0>,
					<MTK_LCM_LK_TYPE_WRITE_PARAM 0>,
					<MTK_LCM_CMD_TYPE_READ_BUFFER 3 0 1 0xBF>,
					<MTK_LCM_TYPE_END>;

				doze_enable_start_table;

				doze_enable_table;

				doze_disable_table;

				doze_area_table;

				doze_post_disp_on_table;

				hbm_set_cmdq_switch_id;
				hbm_set_cmdq_switch_on;
				hbm_set_cmdq_switch_off;
				hbm_set_cmdq_table;

				gpio_test_table = <MTK_LCM_GPIO_TYPE_MODE 2 1 2>,
					<MTK_LCM_GPIO_TYPE_DIR_OUTPUT 2 1 1>,
					<MTK_LCM_GPIO_TYPE_OUT 2 1 1>,
					<MTK_LCM_TYPE_END>;

				/* fps switch cmd for high frame rate feature */
				lcm-ops-dsi-fps-switch-after-poweron {
					compatible =
						"mediatek,lcm-ops-dsi-fps-switch-after-poweron";
					fps-switch-0-1080-2280-60_table;
				};

				lcm-ops-dsi-fps-switch-before-powerdown {
					compatible =
						"mediatek,lcm-ops-dsi-fps-switch-before-powerdown";
					fps-switch-0-1080-2280-60_table;
				};
			};
		};
	};
};

